# CH32F103xx register map
Vendor: WCH Ltd.; File version: 1.0
Registers are 32-bit, read-write, reset 0x0 unless marked. A register's access mark holds for its fields unless they carry their own. Offsets are from the block's base; [hi:lo] are bit positions; {n}, {i} and the like mark numbered series.

## DBG — Debug support
Base 0xE0042000
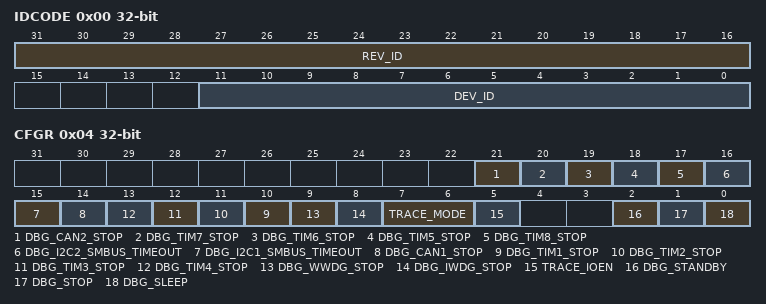
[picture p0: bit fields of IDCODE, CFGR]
0x00 IDCODE ro — DBGMCU_IDCODE
  [31:16] REV_ID, [11:0] DEV_ID
0x04 CFGR — DBGMCU_CFGR
  [21] DBG_CAN2_STOP, [20] DBG_TIM7_STOP, [19] DBG_TIM6_STOP, [18] DBG_TIM5_STOP, [17] DBG_TIM8_STOP, [16] DBG_I2C2_SMBUS_TIMEOUT, [15] DBG_I2C1_SMBUS_TIMEOUT, [14] DBG_CAN1_STOP, [n+9] DBG_TIM{n}_STOP (n=1..4), [9] DBG_WWDG_STOP, [8] DBG_IWDG_STOP, [7:6] TRACE_MODE, [5] TRACE_IOEN, [2] DBG_STANDBY, [1] DBG_STOP, [0] DBG_SLEEP

## CRC — CRC calculation unit
Base 0x40023000
0x00 DATAR reset 0xFFFFFFFF — Data register
  [31:0] DR — Data Register
0x04 IDATAR — Independent Data register
  [7:0] IDATA
0x08 CTLR wo — Control register
  [0] RST — Reset bit

## FLASH
Base 0x40022000
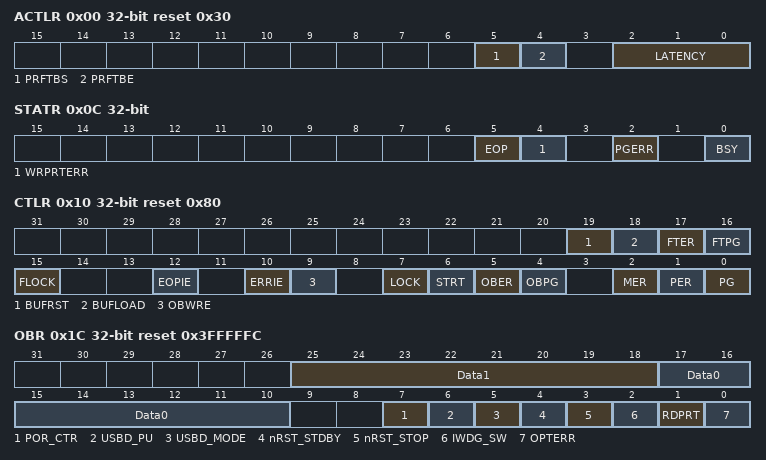
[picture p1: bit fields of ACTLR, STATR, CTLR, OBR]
0x00 ACTLR access per field reset 0x30 — Flash access control register
  [5] PRFTBS ro — Prefetch buffer status
  [4] PRFTBE rw — Prefetch buffer enable
  [2:0] LATENCY rw
0x04 KEYR wo — Flash key register
  [31:0] KEYR — FPEC key
0x08 OBKEYR wo — Flash option key register
  [31:0] OBKEYR — Option byte key
0x0C STATR access per field — Status register
  [5] EOP rw — End of operation
  [4] WRPRTERR rw — Write protection error
  [2] PGERR rw — Programming error
  [0] BSY ro — Busy
0x10 CTLR reset 0x80 — Control register
  [19] BUFRST — execute inner buffer reset
  [18] BUFLOAD — execute data load inner buffer
  [17] FTER — execute fast 128byte erase
  [16] FTPG — execute fast programming
  [15] FLOCK — FAST programming lock
  [12] EOPIE — End of operation interrupt enable
  [10] ERRIE — Error interrupt enable
  [9] OBWRE — Option bytes write enable
  [7] LOCK
  [6] STRT — Start
  [5] OBER — Option byte erase
  [4] OBPG — Option byte programming
  [2] MER — Mass Erase
  [1] PER — Page Erase
  [0] PG — Programming
0x14 ADDR wo — Flash address register
  [31:0] FAR — Flash Address
0x1C OBR ro reset 0x3FFFFFC — Option byte register
  [25:18] Data1
  [17:10] Data0
  [7] POR_CTR — Power on reset time
  [6] USBD_PU — USBD compatible inner pull up resistance configure
  [5] USBD_MODE — USBD compatible speed mode configure
  [4] nRST_STDBY
  [3] nRST_STOP
  [2] IWDG_SW
  [1] RDPRT — Read protection
  [0] OPTERR — Option byte error
0x20 WPR ro reset 0xFFFFFFFF — Write protection register
  [31:0] WRP — Write protect
0x24 MODEKEYR wo — Extension key register
  [31:0] MODEKEYR — high speed write /erase mode ENABLE

## NVIC — Nested Vectored Interrupt Controller
Base 0xE000E000
0x04 ICTR ro — Interrupt Controller Type Register
  [3:0] INTLINESNUM — Total number of interrupt lines in groups
0x100 ISER0 — Interrupt Set-Enable Register
  [31:0] SETENA
0x104 ISER1 — Interrupt Set-Enable Register
  [31:0] SETENA
0x180 ICER0 — Interrupt Clear-Enable Register
  [31:0] CLRENA
0x184 ICER1 — Interrupt Clear-Enable Register
  [31:0] CLRENA
0x200 ISPR0 — Interrupt Set-Pending Register
  [31:0] SETPEND
0x204 ISPR1 — Interrupt Set-Pending Register
  [31:0] SETPEND
0x280 ICPR0 — Interrupt Clear-Pending Register
  [31:0] CLRPEND
0x284 ICPR1 — Interrupt Clear-Pending Register
  [31:0] CLRPEND
0x300 IABR0 ro — Interrupt Active Bit Register
  [31:0] ACTIVE
0x304 IABR1 ro — Interrupt Active Bit Register
  [31:0] ACTIVE
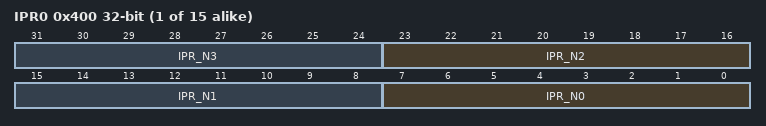
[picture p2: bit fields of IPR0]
{0x400+4i} IPR{i} (i=0..14) — Interrupt Priority Register
  [8n+7:8n] IPR_N{n} (n=0..3)
0xF00 STIR wo — Software Triggered Interrupt Register
  [8:0] INTID — interrupt to be triggered

## USBD — Universal serial bus full-speed device interface
Base 0x40005C00
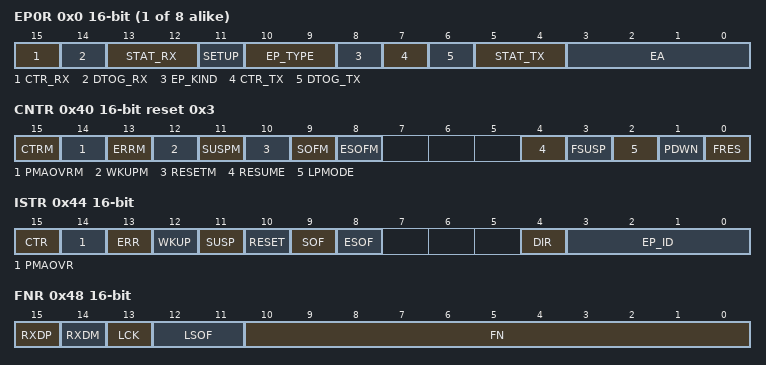
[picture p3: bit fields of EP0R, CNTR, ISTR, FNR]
{0x0+4i} EP{i}R 16-bit (i=0..7) — endpoint {i} register
  [15] CTR_RX — Correct transfer for reception
  [14] DTOG_RX — Data Toggle, for reception transfers
  [13:12] STAT_RX — Status bits, for reception transfers
  [11] SETUP — Setup transaction completed
  [10:9] EP_TYPE — Endpoint type
  [8] EP_KIND — Endpoint kind
  [7] CTR_TX — Correct Transfer for transmission
  [6] DTOG_TX — Data Toggle, for transmission transfers
  [5:4] STAT_TX — Status bits, for transmission transfers
  [3:0] EA — Endpoint address
0x40 CNTR 16-bit reset 0x3 — control register
  [15] CTRM — Correct transfer interrupt mask
  [14] PMAOVRM — Packet memory area over / underrun interrupt mask
  [13] ERRM — Error interrupt mask
  [12] WKUPM — Wakeup interrupt mask
  [11] SUSPM — Suspend mode interrupt mask
  [10] RESETM — USB reset interrupt mask
  [9] SOFM — Start of frame interrupt mask
  [8] ESOFM — Expected start of frame interrupt mask
  [4] RESUME — Resume request
  [3] FSUSP — Force suspend
  [2] LPMODE — Low-power mode
  [1] PDWN — Power down
  [0] FRES — Force USB Reset
0x44 ISTR 16-bit — interrupt status register
  [15] CTR — Correct transfer
  [14] PMAOVR — Packet memory area over / underrun
  [13] ERR — Error
  [12] WKUP — Wakeup
  [11] SUSP — Suspend mode request
  [10] RESET — reset request
  [9] SOF — start of frame
  [8] ESOF — Expected start frame
  [4] DIR — Direction of transaction
  [3:0] EP_ID — Endpoint Identifier
0x48 FNR 16-bit ro — frame number register
  [15] RXDP — Receive data + line status
  [14] RXDM — Receive data - line status
  [13] LCK — Locked
  [12:11] LSOF — Lost SOF
  [10:0] FN — Frame number
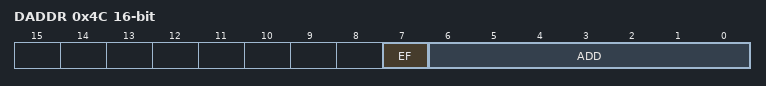
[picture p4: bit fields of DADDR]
0x4C DADDR 16-bit — device address
  [7] EF — Enable function
  [6:0] ADD — Device address
0x50 BTABLE 16-bit — Buffer table address
  [15:3] BTABLE — Buffer table
